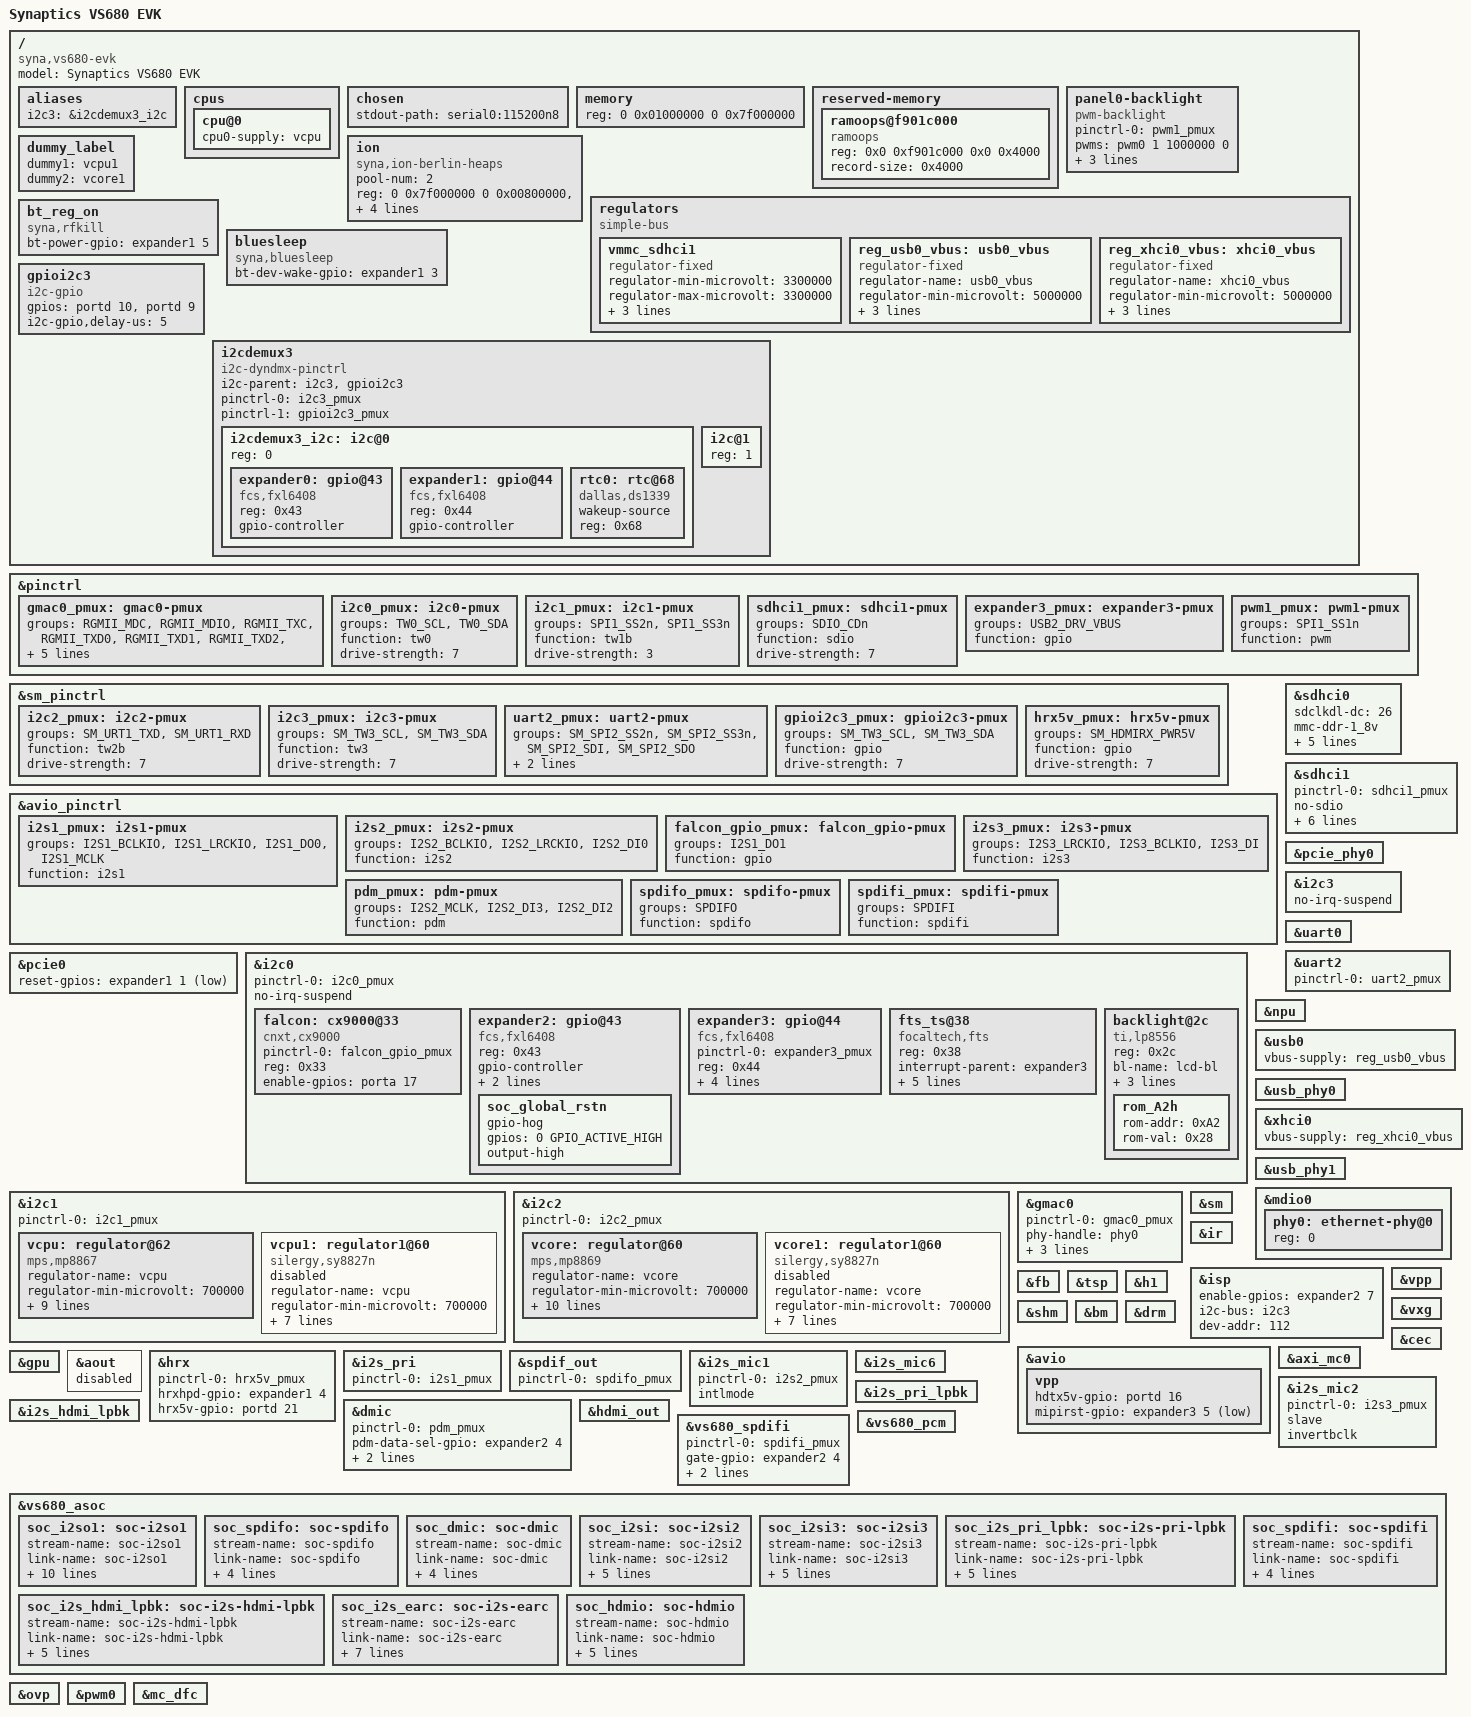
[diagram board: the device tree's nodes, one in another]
// SPDX-License-Identifier: (GPL-2.0 OR MIT)
/*
 * Copyright (C) 2020 Synaptics Incorporated
 *
 * Author: Jisheng Zhang <jszhang@kernel.org>
 */

/dts-v1/;

/memreserve/ 0x7f000000 0x01000000;

#include <dt-bindings/gpio/gpio.h>

#include "vs680-a0.dtsi"

/ {
	model = "Synaptics VS680 EVK";
	compatible = "syna,vs680-evk", "syna,vs680";

	aliases {
		i2c3 = &i2cdemux3_i2c;
	};

	cpus {
		cpu@0 {
			cpu0-supply = <&vcpu>;
		};
	};

	chosen {
		stdout-path = "serial0:115200n8";
	};

	memory {
		device_type = "memory";
		reg = <0 0x01000000 0 0x7f000000>;
	};

	reserved-memory {
		#address-cells = <2>;
		#size-cells = <2>;
		ranges;

		ramoops@f901c000{
			compatible = "ramoops";
			reg = <0x0 0xf901c000 0x0 0x4000>;
			record-size = <0x4000>;
		};
	};

	panel0-backlight {
		compatible = "pwm-backlight";
		pinctrl-names = "default";
		pinctrl-0 = <&pwm1_pmux>;
		pwms = <&pwm0 1 1000000 0>;
		brightness-levels = <0 36 72 108 144 180 212 255>;
		default-brightness-level = <6>;
		enable-gpio = <&expander3 2 GPIO_ACTIVE_HIGH>;
		status = "okay";
	};

	ion {
		compatible = "syna,ion-berlin-heaps";
		pool-num = <2>;
		reg-names = "NonSecure", "Secure";
		reg = <0 0x7f000000 0 0x00800000>,
		      <0 0x7f800000 0 0x00800000>;
		attributes-num-per-pool = <2>;
		pool-attributes = <0x00000105 0x00000F3A 0x00000102 0x00000F3D>;
	};

	regulators {
		compatible = "simple-bus";
		#address-cells = <1>;
		#size-cells = <0>;

		vmmc_sdhci1: vmmc_sdhci1 {
			compatible = "regulator-fixed";
			regulator-min-microvolt = <3300000>;
			regulator-max-microvolt = <3300000>;
			regulator-name = "vmmc_sdio";
			enable-active-high;
			gpio = <&expander3 1 GPIO_ACTIVE_HIGH>;
		};

		reg_usb0_vbus: usb0_vbus {
			compatible = "regulator-fixed";
			regulator-name = "usb0_vbus";
			regulator-min-microvolt = <5000000>;
			regulator-max-microvolt = <5000000>;
			gpio = <&expander2 3 GPIO_ACTIVE_HIGH>;
			enable-active-high;
		};

		reg_xhci0_vbus: xhci0_vbus {
			compatible = "regulator-fixed";
			regulator-name = "xhci0_vbus";
			regulator-min-microvolt = <5000000>;
			regulator-max-microvolt = <5000000>;
			gpio = <&expander2 2 GPIO_ACTIVE_HIGH>;
			enable-active-high;
		};
	};

	dummy_label {
		dummy1 = <&vcpu1>;
		dummy2 = <&vcore1>;
	};

	bt_reg_on: bt_reg_on {
		compatible = "syna,rfkill";
		bt-power-gpio = <&expander1 5 GPIO_ACTIVE_HIGH>;
	};

	bluesleep: bluesleep {
		compatible = "syna,bluesleep";
		bt-dev-wake-gpio = <&expander1 3 GPIO_ACTIVE_HIGH>;
	};

	gpioi2c3: gpioi2c3 {
		#address-cells = <1>;
		#size-cells = <0>;
		compatible = "i2c-gpio";
		gpios = <&portd 10 GPIO_ACTIVE_HIGH /* sda */
			 &portd 9 GPIO_ACTIVE_HIGH /* scl */
			>;
		i2c-gpio,delay-us = <5>;
	};

	i2cdemux3 {
		compatible = "i2c-dyndmx-pinctrl";
		#address-cells = <1>;
		#size-cells = <0>;

		i2c-parent = <&i2c3>, <&gpioi2c3>;

		pinctrl-names = "i2c3", "gpioi2c3";
		pinctrl-0 = <&i2c3_pmux>;
		pinctrl-1 = <&gpioi2c3_pmux>;

		i2cdemux3_i2c: i2c@0 {
			reg = <0>;
			#address-cells = <1>;
			#size-cells = <0>;

			expander0: gpio@43 {
				compatible = "fcs,fxl6408";
				reg = <0x43>;
				gpio-controller;
				#gpio-cells = <2>;
			};

			expander1: gpio@44 {
				compatible = "fcs,fxl6408";
				reg = <0x44>;
				gpio-controller;
				#gpio-cells = <2>;
			};

			rtc0: rtc@68 {
				compatible = "dallas,ds1339";
				wakeup-source;
				reg = <0x68>;
			};
		};

		i2c@1 {
			reg = <1>;
			#address-cells = <1>;
			#size-cells = <0>;
		};
	};
};

&pinctrl {
	gmac0_pmux: gmac0-pmux {
		groups = "RGMII_MDC", "RGMII_MDIO", "RGMII_TXC", "RGMII_TXD0", "RGMII_TXD1", "RGMII_TXD2", "RGMII_TXD3", "RGMII_TXCTL", "RGMII_RXC", "RGMII_RXD0", "RGMII_RXD1", "RGMII_RXD2", "RGMII_RXD3", "RGMII_RXCTL";
		function = "rgmii";
		drive-strength = <3>;
	};

	i2c0_pmux: i2c0-pmux {
		groups = "TW0_SCL", "TW0_SDA";
		function = "tw0";
		drive-strength = <7>;
	};

	i2c1_pmux: i2c1-pmux {
		groups = "SPI1_SS2n", "SPI1_SS3n";
		function = "tw1b";
		drive-strength = <3>;
	};

	sdhci1_pmux: sdhci1-pmux {
		groups = "SDIO_CDn";
		function = "sdio";
		drive-strength = <7>;
	};

	expander3_pmux: expander3-pmux {
		groups = "USB2_DRV_VBUS";
		function = "gpio";
	};

	pwm1_pmux: pwm1-pmux {
		groups = "SPI1_SS1n";
		function = "pwm";
	};
};

&sm_pinctrl {
	i2c2_pmux: i2c2-pmux {
		groups = "SM_URT1_TXD", "SM_URT1_RXD";
		function = "tw2b";
		drive-strength = <7>;
	};

	i2c3_pmux: i2c3-pmux {
		groups = "SM_TW3_SCL", "SM_TW3_SDA";
		function = "tw3";
		drive-strength = <7>;
	};

	uart2_pmux: uart2-pmux {
		groups = "SM_SPI2_SS2n", "SM_SPI2_SS3n", "SM_SPI2_SDI", "SM_SPI2_SDO";
		function = "uart2";
		drive-strength = <3>;
	};

	gpioi2c3_pmux: gpioi2c3-pmux {
		groups = "SM_TW3_SCL", "SM_TW3_SDA";
		function = "gpio";
		drive-strength = <7>;
	};

	hrx5v_pmux: hrx5v-pmux {
		groups = "SM_HDMIRX_PWR5V";
		function = "gpio";
		drive-strength = <7>;
	};
};

&avio_pinctrl {
	i2s1_pmux: i2s1-pmux {
		groups = "I2S1_BCLKIO", "I2S1_LRCKIO", "I2S1_DO0", "I2S1_MCLK";
		function = "i2s1";
	};

	i2s2_pmux: i2s2-pmux {
		groups = "I2S2_BCLKIO", "I2S2_LRCKIO", "I2S2_DI0";
		function = "i2s2";
	};

	falcon_gpio_pmux: falcon_gpio-pmux {
		groups = "I2S1_DO1";
		function = "gpio";
	};

	i2s3_pmux: i2s3-pmux {
		groups = "I2S3_LRCKIO", "I2S3_BCLKIO", "I2S3_DI";
		function = "i2s3";
	};

	pdm_pmux: pdm-pmux {
		groups = "I2S2_MCLK", "I2S2_DI3", "I2S2_DI2";
		function = "pdm";
	};

	spdifo_pmux: spdifo-pmux {
		groups = "SPDIFO";
		function = "spdifo";
	};

	spdifi_pmux: spdifi-pmux {
		groups = "SPDIFI";
		function = "spdifi";
	};

};

&sdhci0 {
	status = "okay";
	sdclkdl-dc = /bits/ 8 <26>;
	mmc-ddr-1_8v;
	mmc-hs200-1_8v;
	mmc-hs400-1_8v;
	dll-calibration;
	pad-sp = /bits/ 8 <14>;
	pad-sn = /bits/ 8 <14>;
};

&sdhci1 {
	status = "okay";
	pinctrl-0 = <&sdhci1_pmux>;
	pinctrl-names = "default";
	no-sdio;
	no-mmc;
	disable-wp;
	sdclkdl-dc = /bits/ 8 <75>;
	pad-sp = /bits/ 8 <12>;
	pad-sn = /bits/ 8 <12>;
	vmmc-supply = <&vmmc_sdhci1>;
};

&pcie_phy0 {
	status = "okay";
};

&pcie0 {
	status = "okay";
	reset-gpios = <&expander1 1 GPIO_ACTIVE_LOW>;
};

&i2c0 {
	status = "okay";
	pinctrl-names = "default";
	pinctrl-0 = <&i2c0_pmux>;
	no-irq-suspend;

	falcon: cx9000@33 {
		compatible = "cnxt,cx9000";
		pinctrl-names = "default";
		pinctrl-0 = <&falcon_gpio_pmux>;

		#sound-dai-cells = <0>;
		reg = <0x33>;
		enable-gpios=<&porta 17 GPIO_ACTIVE_HIGH>;
		status = "okay";
	};

	expander2: gpio@43 {
		compatible = "fcs,fxl6408";
		reg = <0x43>;
		gpio-controller;
		#gpio-cells = <2>;
		shutdown-mask = /bits/ 8 <0x1>;
		shutdown-val = /bits/ 8 <0x0>;

		soc_global_rstn {
			gpio-hog;
			gpios = <0 GPIO_ACTIVE_HIGH>;
			output-high;
		};
	};

	expander3: gpio@44 {
		compatible = "fcs,fxl6408";
		pinctrl-names = "default";
		pinctrl-0 = <&expander3_pmux>;
		reg = <0x44>;
		gpio-controller;
		#gpio-cells = <2>;
		interrupt-parent = <&portb>;
		interrupts = <23 IRQ_TYPE_NONE>;
		interrupt-controller;
		#interrupt-cells = <2>;
		#address-cells = <0>;
	};

	fts_ts@38 {
		compatible = "focaltech,fts";
		status = "okay";
		reg = <0x38>;
		interrupt-parent = <&expander3>;
		interrupts = <4 0>;
		focaltech,irq-gpio = <&expander3 4 0>;
		focaltech,reset-gpio = <&expander3 5 GPIO_ACTIVE_LOW>;
		focaltech,display-coords = <0 0 799 1279>;
		focaltech,max-touch-number = <5>;
	};

	backlight@2c {
		compatible = "ti,lp8556";
		reg = <0x2c>;
		bl-name = "lcd-bl";
		dev-ctrl = /bits/ 8 <0x05>;
		init-brt = /bits/ 8 <0xFF>;
		pwm-period = /bits/ 8 <0x00>;

		/* CFG2 */
		rom_A2h {
			rom-addr = /bits/ 8 <0xA2>;
			rom-val = /bits/ 8 <0x28>;
		};
	};
};

&i2c1 {
	status = "okay";
	pinctrl-names = "default";
	pinctrl-0 = <&i2c1_pmux>;

	vcpu: regulator@62 {
		compatible = "mps,mp8867";
		regulator-name = "vcpu";
		regulator-min-microvolt = <700000>;
		regulator-max-microvolt = <980000>;
		regulator-always-on;
		regulator-boot-on;
		enable-gpios = <&expander0 1 GPIO_ACTIVE_LOW>;
		mps,fb-voltage-divider = <80 240>;
		regulator-active-discharge = <0>;
		mps,switch-frequency-hz = <1500000>;
		mps,vsel-step = <1>;
		reg = <0x62>;
	};

	vcpu1: regulator1@60 {
		status = "disabled";
		compatible = "silergy,sy8827n";
		regulator-name = "vcpu";
		regulator-min-microvolt = <700000>;
		regulator-max-microvolt = <987500>;
		regulator-always-on;
		regulator-boot-on;
		regulator-active-discharge = <0>;
		enable-gpios = <&expander0 1 GPIO_ACTIVE_LOW>;
		silergy,vsel-step = <1>;
		reg = <0x60>;
	};
};

&i2c2 {
	status = "okay";
	pinctrl-names = "default";
	pinctrl-0 = <&i2c2_pmux>;

	vcore: regulator@60 {
		compatible = "mps,mp8869";
		regulator-name = "vcore";
		regulator-min-microvolt = <700000>;
		regulator-max-microvolt = <900000>;
		regulator-always-on;
		regulator-boot-on;
		enable-gpios = <&expander0 0 GPIO_ACTIVE_LOW>;
		mps,fb-voltage-divider = <80 240>;
		regulator-active-discharge = <0>;
		mps,switch-frequency-hz = <1250000>;
		mps,vsel-step = <1>;
		regulator-ramp-delay = <40000>;
		reg = <0x60>;
	};

	vcore1: regulator1@60 {
		status = "disabled";
		compatible = "silergy,sy8827n";
		regulator-name = "vcore";
		regulator-min-microvolt = <700000>;
		regulator-max-microvolt = <937500>;
		regulator-always-on;
		regulator-boot-on;
		regulator-active-discharge = <0>;
		enable-gpios = <&expander0 0 GPIO_ACTIVE_LOW>;
		silergy,vsel-step = <1>;
		reg = <0x60>;
	};
};

&i2c3 {
	status = "okay";
	no-irq-suspend;
};

&uart0 {
	status = "okay";
};

&uart2 {
	status = "okay";
	pinctrl-0 = <&uart2_pmux>;
	pinctrl-names = "default";
};

&npu {
	status = "okay";
};

&usb0 {
	vbus-supply = <&reg_usb0_vbus>;
	status = "okay";
};

&usb_phy0  {
	status = "okay";
};

&xhci0 {
	vbus-supply = <&reg_xhci0_vbus>;
	status = "okay";
};

&usb_phy1  {
	status = "okay";
};

&mdio0 {
	phy0: ethernet-phy@0 {
		reg = <0>;
	};
};

&gmac0 {
	status = "okay";
	pinctrl-0 = <&gmac0_pmux>;
	pinctrl-names = "default";
	phy-handle = <&phy0>;
	phy-mode = "rgmii-id";
	snps,reset-gpio = <&expander1 0 GPIO_ACTIVE_LOW>;
	snps,reset-delays-us = <0 10000 50000>;
};

&sm {
	status = "okay";
};

&ir {
	status = "okay";
};

&isp {
	status = "okay";
	enable-gpios = <&expander2 7 GPIO_ACTIVE_HIGH>;
	i2c-bus = <&i2c3>;
	dev-addr = <112>;
};

&vpp {
	status = "okay";
};

&fb {
	status = "okay";
};

&tsp {
	status = "okay";
};

&h1 {
	status = "okay";
};

&vxg {
	status = "okay";
};

&shm {
	status = "okay";
};

&bm {
	status = "okay";
};

&drm {
	status = "okay";
};

&avio {
	status = "okay";
	vpp {
		hdtx5v-gpio = <&portd 16 GPIO_ACTIVE_HIGH>;
		mipirst-gpio = <&expander3 5 GPIO_ACTIVE_LOW>;
	};
};

&cec {
	status = "okay";
};

&axi_mc0 {
	status = "okay";
};

&gpu {
	status = "okay";
};

&aout {
	status = "disabled";
};

&hrx {
	status = "okay";
	pinctrl-0 = <&hrx5v_pmux>;
	pinctrl-names = "default";
	hrxhpd-gpio = <&expander1 4 GPIO_ACTIVE_HIGH>;
	hrx5v-gpio = <&portd 21 GPIO_ACTIVE_HIGH>;
};

&i2s_pri {
	status = "okay";
	pinctrl-0 = <&i2s1_pmux>;
	pinctrl-names = "default";
};

&spdif_out {
	status = "okay";
	pinctrl-0 = <&spdifo_pmux>;
	pinctrl-names = "default";
};

&i2s_mic1 {
	status = "okay";
	pinctrl-0 = <&i2s2_pmux>;
	pinctrl-names = "default";
	intlmode;
};

&dmic {
	status = "okay";
	pinctrl-0 = <&pdm_pmux>;
	pinctrl-names = "default";
	pdm-data-sel-gpio = <&expander2 4 GPIO_ACTIVE_HIGH>;
	pdm-type = <1>;
	pdm-clk-sel = <2>;
};

&i2s_mic2 {
	status = "okay";
	pinctrl-0 = <&i2s3_pmux>;
	pinctrl-names = "default";
	slave;
	invertbclk;
};

&i2s_mic6 {
	status = "okay";
};

&i2s_pri_lpbk {
	status = "okay";
};

&i2s_hdmi_lpbk {
	status = "okay";
};

&hdmi_out {
	status = "okay";
};

&vs680_spdifi {
	status = "okay";
	pinctrl-0 = <&spdifi_pmux>;
	pinctrl-names = "default";
	gate-gpio = <&expander2 4 GPIO_ACTIVE_HIGH>;
	enable-gpio = <&expander3 7 GPIO_ACTIVE_LOW>;
	dynamic-src-ctrl;
};

&vs680_pcm {
	status = "okay";
};

&vs680_asoc {
	status = "okay";

	soc_i2so1: soc-i2so1 {
		status = "okay";
		stream-name = "soc-i2so1";
		link-name = "soc-i2so1";
		format = "i2s";
		continuous-clock;
		bitclock-inversion;
		frame-inversion;
		bitclock-master;
		frame-master;
		cpu-node = <&i2s_pri>;
		codec-name = "cx9000.0-0033";
		codec-dai-name = "cx9000-amplifier";
		platform-node = <&vs680_pcm>;
	};

	soc_spdifo: soc-spdifo {
		status = "okay";
		stream-name = "soc-spdifo";
		link-name = "soc-spdifo";
		cpu-node = <&spdif_out>;
		codec-name = "snd-soc-dummy";
		codec-dai-name = "snd-soc-dummy-dai";
		platform-node = <&vs680_pcm>;
	};

	soc_dmic: soc-dmic {
		status = "okay";
		stream-name = "soc-dmic";
		link-name = "soc-dmic";
		cpu-node = <&dmic>;
		codec-name = "snd-soc-dummy";
		codec-dai-name = "snd-soc-dummy-dai";
		platform-node = <&vs680_pcm>;
	};

	soc_i2si: soc-i2si2 {
		status = "okay";
		stream-name = "soc-i2si2";
		link-name = "soc-i2si2";
		format = "i2s";
		cpu-node = <&i2s_mic1>;
		codec-name = "snd-soc-dummy";
		codec-dai-name = "snd-soc-dummy-dai";
		platform-node = <&vs680_pcm>;
	};

	soc_i2si3: soc-i2si3 {
		status = "okay";
		stream-name = "soc-i2si3";
		link-name = "soc-i2si3";
		format = "i2s";
		cpu-node = <&i2s_mic2>;
		codec-name = "snd-soc-dummy";
		codec-dai-name = "snd-soc-dummy-dai";
		platform-node = <&vs680_pcm>;
	};

	soc_i2s_pri_lpbk: soc-i2s-pri-lpbk {
		status = "okay";
		stream-name = "soc-i2s-pri-lpbk";
		link-name = "soc-i2s-pri-lpbk";
		format = "i2s";
		cpu-node = <&i2s_pri_lpbk>;
		codec-name = "snd-soc-dummy";
		codec-dai-name = "snd-soc-dummy-dai";
		platform-node = <&vs680_pcm>;
	};

	soc_i2s_hdmi_lpbk: soc-i2s-hdmi-lpbk {
		status = "okay";
		stream-name = "soc-i2s-hdmi-lpbk";
		link-name = "soc-i2s-hdmi-lpbk";
		format = "i2s";
		cpu-node = <&i2s_hdmi_lpbk>;
		codec-name = "snd-soc-dummy";
		codec-dai-name = "snd-soc-dummy-dai";
		platform-node = <&vs680_pcm>;
	};

	soc_spdifi: soc-spdifi {
		status = "okay";
		stream-name = "soc-spdifi";
		link-name = "soc-spdifi";
		cpu-node = <&vs680_spdifi>;
		codec-name = "snd-soc-dummy";
		codec-dai-name = "snd-soc-dummy-dai";
		platform-node = <&vs680_pcm>;
	};

	soc_i2s_earc: soc-i2s-earc {
		status = "okay";
		stream-name = "soc-i2s-earc";
		link-name = "soc-i2s-earc";
		format = "i2s";
		bitclock-master;
		frame-master;
		cpu-node = <&i2s_mic6>;
		codec-name = "snd-soc-dummy";
		codec-dai-name = "snd-soc-dummy-dai";
		platform-node = <&vs680_pcm>;
	};

        soc_hdmio: soc-hdmio {
                status = "okay";
                stream-name = "soc-hdmio";
                link-name = "soc-hdmio";
                format = "i2s";
                cpu-node = <&hdmi_out>;
                codec-name = "snd-soc-dummy";
                codec-dai-name = "snd-soc-dummy-dai";
                platform-node = <&vs680_pcm>;
        };
};

&ovp {
	status = "okay";
};

&pwm0 {
	status = "okay";
};

&mc_dfc {
	status = "okay";
};
